# MKL34Z4 register map
Vendor: Freescale Semiconductor, Inc.; File version: 1.6
CPU: CM0PLUS r0p0, little endian, no MPU, no FPU, 0x2 interrupt priority bits, 0x0 interrupts
Registers are 32-bit, read-write, reset 0x0 unless marked. A register's access mark holds for its fields unless they carry their own. Offsets are from the block's base; [hi:lo] are bit positions; {n}, {i} and the like mark numbered series; 'fields as' and 'values as' point back to an identical list.

## MTB — Micro Trace Buffer
Base 0xF0000000; register names take the prefix MTB_
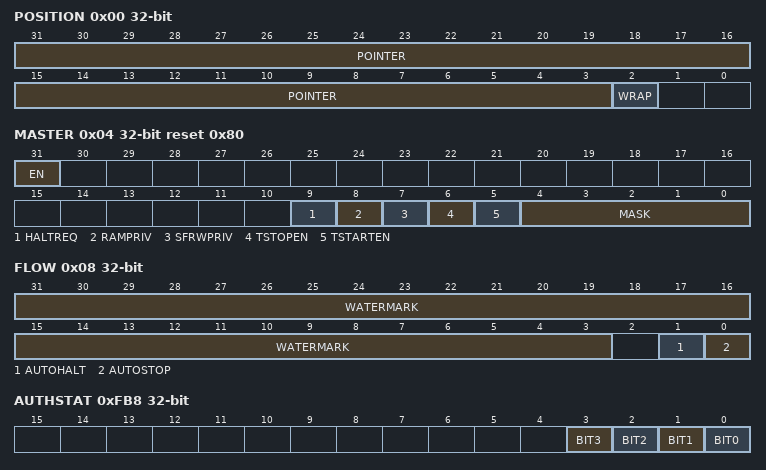
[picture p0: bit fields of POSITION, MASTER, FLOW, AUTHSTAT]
0x00 POSITION (reset mask 0x3) — MTB Position Register
  [31:3] POINTER — Trace Packet Address Pointer[28:0]
  [2] WRAP — This bit is set to 1 automatically when the POINTER value wraps as determined by the MTB_MASTER[MASK] field in the MASTER Trace Control Register
0x04 MASTER reset 0x80 (reset mask 0xFFFFFFE0) — MTB Master Register
  [31] EN — Main trace enable bit
  [9] HALTREQ — Halt request bit
  [8] RAMPRIV — RAM privilege bit
  [7] SFRWPRIV — Special Function Register Write Privilege bit
  [6] TSTOPEN — Trace stop input enable
  [5] TSTARTEN — Trace start input enable
  [4:0] MASK
0x08 FLOW (reset mask 0x4) — MTB Flow Register
  [31:3] WATERMARK — WATERMARK[28:0]
  [1] AUTOHALT — If this bit is 1 and WATERMARK is equal to MTB_POSITION[POINTER], then the MTB_MASTER[HALTREQ] bit is automatically set to 1
  [0] AUTOSTOP — If this bit is 1 and WATERMARK is equal to MTB_POSITION[POINTER], then the MTB_MASTER[EN] bit is automatically set to 0
0x0C BASE ro reset not defined — MTB Base Register
  [31:0] BASEADDR — This value is defined with a hardwired signal and the expression: 0x2000_0000 - (RAM_Size/4)
0xF00 MODECTRL ro — Integration Mode Control Register
  [31:0] MODECTRL — Hardwired to 0x0000_0000
0xFA0 TAGSET ro — Claim TAG Set Register
  [31:0] TAGSET — Hardwired to 0x0000_0000
0xFA4 TAGCLEAR ro — Claim TAG Clear Register
  [31:0] TAGCLEAR — Hardwired to 0x0000_0000
0xFB0 LOCKACCESS ro
  [31:0] LOCKACCESS — Hardwired to 0x0000_0000
0xFB4 LOCKSTAT ro — Lock Status Register
  [31:0] LOCKSTAT — Hardwired to 0x0000_0000
0xFB8 AUTHSTAT ro — Authentication Status Register
  [3] BIT3 — Hardwired to 1.
  [2] BIT2 — Connected to NIDEN or DBGEN signal.
  [1] BIT1 — Hardwired to 1.
  [0] BIT0 — Connected to DBGEN.
0xFBC DEVICEARCH ro reset 0x47700A31 — Device Architecture Register
  [31:0] DEVICEARCH — Hardwired to 0x4770_0A31.
0xFC8 DEVICECFG ro — Device Configuration Register
  [31:0] DEVICECFG — Hardwired to 0x0000_0000.
0xFCC DEVICETYPID ro reset 0x31 — Device Type Identifier Register
  [31:0] DEVICETYPID — Hardwired to 0x0000_0031.
{0xFC0+4i} PERIPHID{i} ro reset not defined (i=4..7) — Peripheral ID Register
  [31:0] PERIPHID — Peripheral ID4 is hardwired to 0x0000_0004; ID0 to 0x0000_0032; ID1 to 0x0000_00B9; ID2 to 0x0000_000B; and all the others to 0x0000_0000
{0xFE0+4i} PERIPHID{i} ro reset not defined (i=0..3) — Peripheral ID Register
  fields as PERIPHID4
{0xFF0+4i} COMPID{i} ro reset not defined (i=0..3) — Component ID Register
  [31:0] COMPID — Component ID

## MTBDWT — MTB data watchpoint and trace
Base 0xF0001000; register names take the prefix MTBDWT_
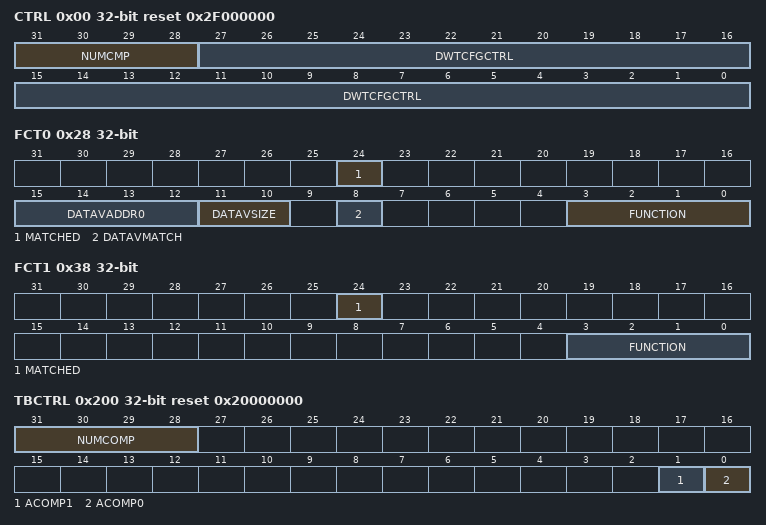
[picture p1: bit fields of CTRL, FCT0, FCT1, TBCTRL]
0x00 CTRL ro reset 0x2F000000 — MTB DWT Control Register
  [31:28] NUMCMP — Number of comparators
  [27:0] DWTCFGCTRL — DWT configuration controls
0x20 COMP0 — MTB_DWT Comparator Register
  [31:0] COMP — Reference value for comparison
0x24 MASK0 — MTB_DWT Comparator Mask Register
  [4:0] MASK
0x28 FCT0 — MTB_DWT Comparator Function Register 0
  [24] MATCHED ro — Comparator match
    0=No match; 1=Match occurred
  [15:12] DATAVADDR0 — Data Value Address 0
  [11:10] DATAVSIZE — Data Value Size
    0=Byte; 1=Halfword; 2=Word; 3=Reserved. Any attempts to use this value results in UNPREDICTABLE behavior.
  [8] DATAVMATCH — Data Value Match
    0=Perform address comparison; 1=Perform data value comparison
  [3:0] FUNCTION
    0=Disabled; 4=Instruction fetch; 5=Data operand read; 6=Data operand write; 7=Data operand (read + write)
0x30 COMP1 — MTB_DWT Comparator Register
  [31:0] COMP — Reference value for comparison
0x34 MASK1 — MTB_DWT Comparator Mask Register
  [4:0] MASK
0x38 FCT1 — MTB_DWT Comparator Function Register 1
  [24] MATCHED ro — Comparator match
    0=No match; 1=Match occurred
  [3:0] FUNCTION
    values as FCT0.FUNCTION
0x200 TBCTRL reset 0x20000000 — MTB_DWT Trace Buffer Control Register
  [31:28] NUMCOMP ro — Number of Comparators
  [1] ACOMP1 — Action based on Comparator 1 match
    0=Trigger TSTOP based on the assertion of MTBDWT_FCT1[MATCHED]; 1=Trigger TSTART based on the assertion of MTBDWT_FCT1[MATCHED]
  [0] ACOMP0 — Action based on Comparator 0 match
    0=Trigger TSTOP based on the assertion of MTBDWT_FCT0[MATCHED]; 1=Trigger TSTART based on the assertion of MTBDWT_FCT0[MATCHED]
0xFC8 DEVICECFG ro — Device Configuration Register
  [31:0] DEVICECFG — Hardwired to 0x0000_0000.
0xFCC DEVICETYPID ro reset 0x4 — Device Type Identifier Register
  [31:0] DEVICETYPID — Hardwired to 0x0000_0004.
{0xFC0+4i} PERIPHID{i} ro reset not defined (i=4..7) — Peripheral ID Register
  [31:0] PERIPHID — Peripheral ID1 is hardwired to 0x0000_00E0; ID2 to 0x0000_0008; and all the others to 0x0000_0000.
{0xFE0+4i} PERIPHID{i} ro reset not defined (i=0..3) — Peripheral ID Register
  fields as PERIPHID4
{0xFF0+4i} COMPID{i} ro reset not defined (i=0..3) — Component ID Register
  [31:0] COMPID — Component ID

## ROM — System ROM
Base 0xF0002000; register names take the prefix ROM_
Registers as MTBDWT, without CTRL, COMP0, MASK0, FCT0, COMP1, MASK1, FCT1, TBCTRL, DEVICECFG, DEVICETYPID; these are added or differ:
{0x0+4i} ENTRY{i} ro reset not defined (i=0..2) — Entry
  [31:0] ENTRY
0x0C TABLEMARK ro — End of Table Marker Register
  [31:0] MARK — Hardwired to 0x0000_0000
0xFCC SYSACCESS ro reset 0x1 — System Access Register
  [31:0] SYSACCESS — Hardwired to 0x0000_0001

## MCM — Core Platform Miscellaneous Control Module
Base 0xF0003000; register names take the prefix MCM_
0x08 PLASC 16-bit ro reset 0x7 — Crossbar Switch (AXBS) Slave Configuration
  [7:0] ASC — Each bit in the ASC field indicates whether there is a corresponding connection to the crossbar switch's slave input port.
    0=A bus slave connection to AXBS input port n is absent; 1=A bus slave connection to AXBS input port n is present
0x0A PLAMC 16-bit ro reset 0xD — Crossbar Switch (AXBS) Master Configuration
  [7:0] AMC — Each bit in the AMC field indicates whether there is a corresponding connection to the AXBS master input port.
    0=A bus master connection to AXBS input port n is absent; 1=A bus master connection to AXBS input port n is present
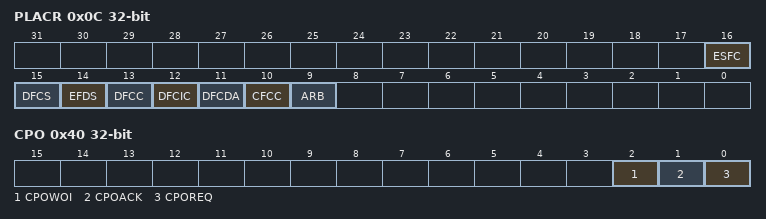
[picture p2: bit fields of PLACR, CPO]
0x0C PLACR — Platform Control Register
  [16] ESFC — Enable Stalling Flash Controller
    0=Disable stalling flash controller when flash is busy; 1=Enable stalling flash controller when flash is busy
  [15] DFCS — Disable Flash Controller Speculation
    0=Enable flash controller speculation; 1=Disable flash controller speculation
  [14] EFDS — Enable Flash Data Speculation
    0=Disable flash data speculation; 1=Enable flash data speculation
  [13] DFCC — Disable Flash Controller Cache
    0=Enable flash controller cache; 1=Disable flash controller cache
  [12] DFCIC — Disable Flash Controller Instruction Caching
    0=Enable flash controller instruction caching; 1=Disable flash controller instruction caching
  [11] DFCDA — Disable Flash Controller Data Caching
    0=Enable flash controller data caching; 1=Disable flash controller data caching
  [10] CFCC wo — Clear Flash Controller Cache
  [9] ARB — Arbitration select
    0=Fixed-priority arbitration for the crossbar masters; 1=Round-robin arbitration for the crossbar masters
0x40 CPO — Compute Operation Control Register
  [2] CPOWOI — Compute Operation wakeup on interrupt
    0=No effect; 1=When set, the CPOREQ is cleared on any interrupt or exception vector fetch
  [1] CPOACK ro — Compute Operation acknowledge
    0=Compute operation entry has not completed or compute operation exit has completed; 1=Compute operation entry has completed or compute operation exit has not completed
  [0] CPOREQ — Compute Operation request
    0=Request is cleared; 1=Request Compute Operation
